# max32572 register map
Vendor: Maxim-Integrated; Series: ARMCM4; File version: 1.0
CPU: CM4 r2p1, little endian, MPU, FPU, 3 interrupt priority bits
Registers are 32-bit, read-write, reset 0x0 unless marked. A register's access mark holds for its fields unless they carry their own. Offsets are from the block's base; [hi:lo] are bit positions; {n}, {i} and the like mark numbered series.

## SEMA — The Semaphore peripheral allows multiple cores in a system to cooperate when accessing shred resources. The peripheral contains eight semaphores that can be atomically set and cleared. It is left to the discretion of the software architect to decide how and when the semaphores are used and how they are allocated. Existing hardware does not have to be modified for this type of cooperative sharing, and the use of semaphores is exclusively within the software domain.
Base 0x4003E000
{0x0+4i} SEMAPHORES[{i}] (i=0..7) — Read to test and set, returns prior value. Write 0 to clear semaphore.
  [0] sema
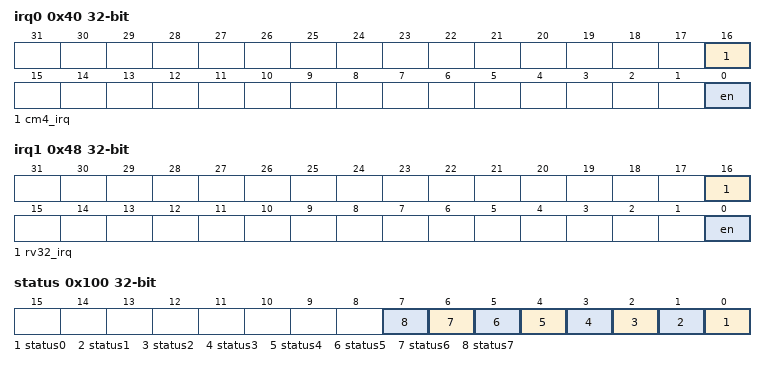
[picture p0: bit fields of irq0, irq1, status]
0x40 irq0 — Semaphore IRQ0 register.
  [16] cm4_irq, [0] en
0x44 mail0 — Semaphore Mailbox 0 register.
  [31:0] data
0x48 irq1 — Semaphore IRQ1 register.
  [16] rv32_irq, [0] en
0x4C mail1 — Semaphore Mailbox 1 register.
  [31:0] data
0x100 status — Semaphore status bits. 0 indicates the semaphore is free, 1 indicates taken.
  [n] status{n} (n=0..7)

## SCN — Smart Card Interface.
Base 0x4002C000
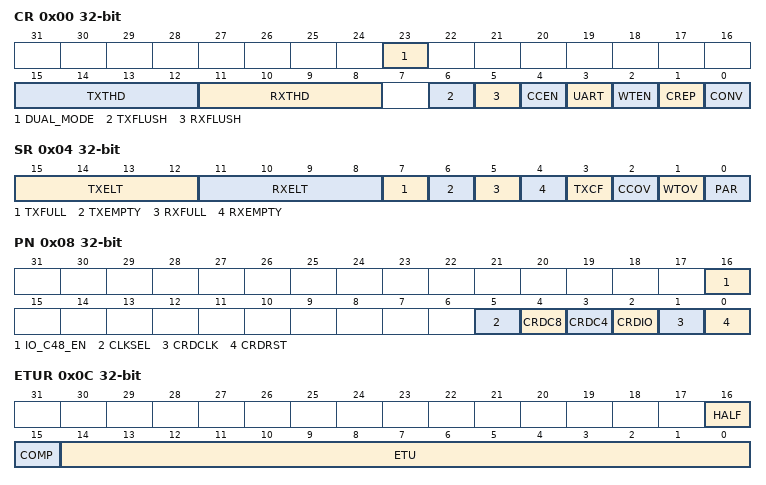
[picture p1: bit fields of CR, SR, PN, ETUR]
0x00 CR — Control Register.
  [23] DUAL_MODE — Dual Internal AFE and Bypass Mode.
  [15:12] TXTHD — Transmit FIFO Depth.
  [11:8] RXTHD — Receive FIFO Depth.
  [6] TXFLUSH — Transmit FIFO Flush.
  [5] RXFLUSH — Receive FIFO Flush.
  [4] CCEN — Clock Counter Enable Bit.
  [3] UART — Smart Card Mode Bit.
  [2] WTEN — Wait Time Counter Enable Bit.
  [1] CREP — Character Repeat Enable Bit.
  [0] CONV — Convention Select Bit.
0x04 SR — Status Register.
  [15:12] TXELT — Number of Bytes in the Transmit FIFO.
  [11:8] RXELT — Number of Bytes in the Receive FIFO.
  [7] TXFULL — Transmit FIFO Full Flag.
  [6] TXEMPTY — Transmit FIFO Empty Flag.
  [5] RXFULL — Receive FIFO Full Flag.
  [4] RXEMPTY — Receive FIFO Empty Flag.
  [3] TXCF — Transmit Complete Flag.
  [2] CCOV — Clock Counter Overflow Flag.
  [1] WTOV — Waiting Time Counter Overflow.
  [0] PAR — Parity Error Detector Flag.
0x08 PN — Pin Register.
  [16] IO_C48_EN — Pin Enable.
  [5] CLKSEL — Smart Card Clock Select.
  [4] CRDC8 — Smart Card SCn_C8 Pin Control.
  [3] CRDC4 — Smart Card SCn_C4 Pin Control.
  [2] CRDIO — Smart Card IO Pin Control.
  [1] CRDCLK — Smart Card Clock Piin Control.
  [0] CRDRST — Smart Card Reset Pin Control.
0x0C ETUR — ETU Register.
  [16] HALF — Half ETU Count Selection Bit.
  [15] COMP — Compensation Mode Enable Bit.
  [14:0] ETU — Elemental Time Unit Value.
0x10 GTR — Guard Time Register.
  [15:0] GT — Guard Time.
0x14 WT0R — Waiting Time 0 Register.
  [31:0] WT — Wait Time.
0x18 WT1R — Waiting Time 1 Register.
  [7:0] WT — Wait Time.
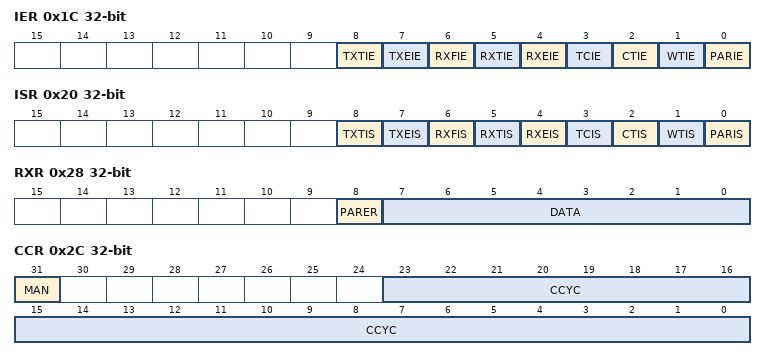
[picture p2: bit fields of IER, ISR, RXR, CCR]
0x1C IER — Interrupt Enable Register.
  [8] TXTIE — Transmit FIFO Threshold Reached Interrupt Enable.
  [7] TXEIE — Transmit FIFO Empty Interrupt Enable.
  [6] RXFIE — Receive FIFO Full Interrupt Enable.
  [5] RXTIE — Receive FIFO Threshold Reached Interrupt Enable.
  [4] RXEIE — Receive FIFO Empty Interrupt Enable.
  [3] TCIE — Character Transmission Completion Interrupt Enable.
  [2] CTIE — Clock Counter Overflow Interrupt Enable.
  [1] WTIE — Waiting Time Overflow Interrupt Enable.
  [0] PARIE — Parity Error Interrupt Enable.
0x20 ISR — Interrupt Status Register.
  [8] TXTIS — Transmit FIFO Threshold Reached Interrupt Status Flag.
  [7] TXEIS — Transmit FIFO Empty Interrupt Status Flag.
  [6] RXFIS — Receive FIFO Full Interrupt Status Flag.
  [5] RXTIS — Receive FIFO Threshold Reached Interrupt Status Flag.
  [4] RXEIS — Receive FIFO Empty Interrupt Status Flag.
  [3] TCIS — Character Transmission Completion Interrupt Status Flag.
  [2] CTIS — Clock Counter Overflow Interrupt Status Flag.
  [1] WTIS — Waiting Time Overflow Interrupt Status Flag.
  [0] PARIS — Parity Error Interrupt Status Flag.
0x24 TXR — Transmit Register.
  [7:0] DATA — Transmit Data.
0x28 RXR — Receive Register.
  [8] PARER — Parity Error Detect Bit.
  [7:0] DATA — Receive Data.
0x2C CCR — Clock Counter Register.
  [31] MAN — Manual Mode.
  [23:0] CCYC — Number of Clock Cycles to Count.
